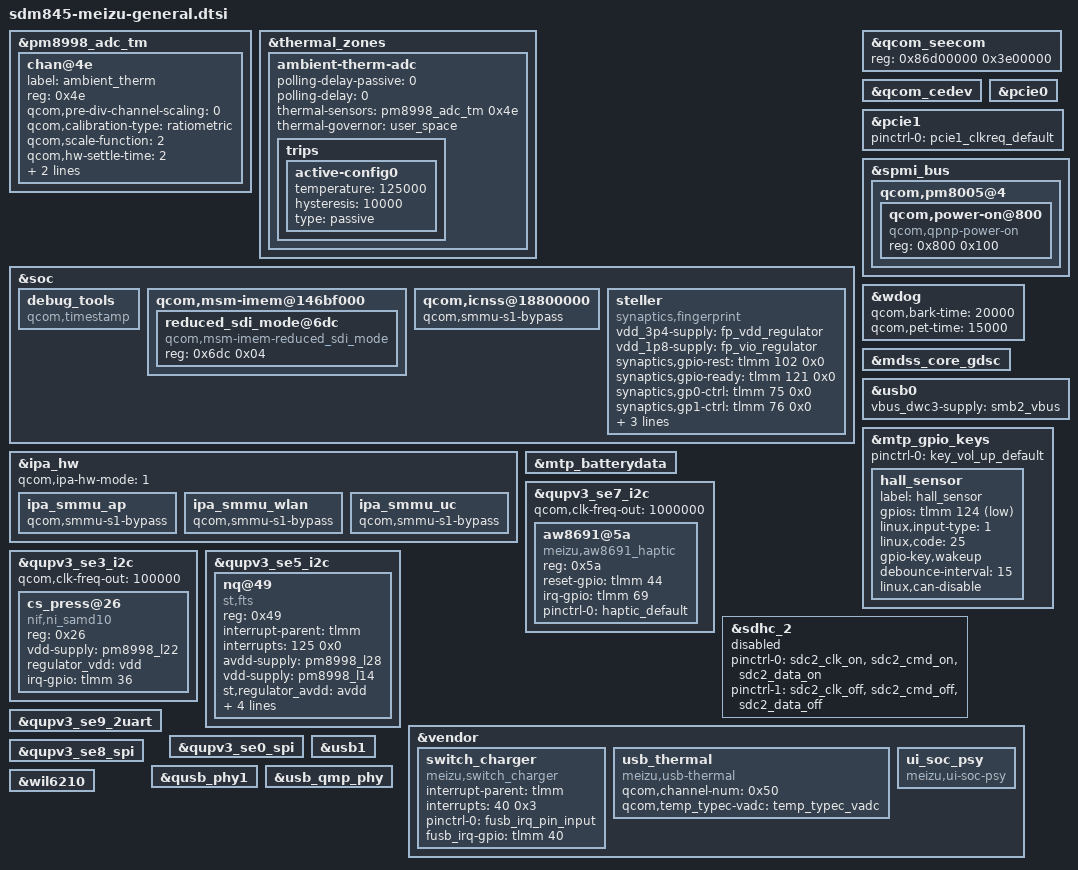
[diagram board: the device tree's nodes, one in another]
/* Copyright (c) 2022, MeizuCustoms enthusiasts
 *
 * This program is free software; you can redistribute it and/or modify
 * it under the terms of the GNU General Public License version 2 and
 * only version 2 as published by the Free Software Foundation.
 *
 * This program is distributed in the hope that it will be useful,
 * but WITHOUT ANY WARRANTY; without even the implied warranty of
 * MERCHANTABILITY or FITNESS FOR A PARTICULAR PURPOSE.  See the
 * GNU General Public License for more details.
 */

&pm8998_adc_tm {
    chan@4e {
        label = "ambient_therm";
        reg = <0x4e>;
        qcom,pre-div-channel-scaling = <0>;
        qcom,calibration-type = "ratiometric";
        qcom,scale-function = <2>;
        qcom,hw-settle-time = <2>;
        qcom,btm-channel-number = <136>;
        qcom,thermal-node;
    };
};

&thermal_zones {
    ambient-therm-adc {
        polling-delay-passive = <0>;
        polling-delay = <0>;
        thermal-sensors = <&pm8998_adc_tm 0x4e>;
        thermal-governor = "user_space";

        trips {

            active-config0 {
                temperature = <125000>;
                hysteresis = <10000>;
                type = "passive";
            };
        };
    };
};

&soc {
    debug_tools {
        status = "ok";
        compatible = "qcom,timestamp";
    };

    qcom,msm-imem@146bf000 {
        reduced_sdi_mode@6dc {
            compatible = "qcom,msm-imem-reduced_sdi_mode";
            reg = <0x6dc 0x04>;
        };
    };

    qcom,icnss@18800000 {
        qcom,smmu-s1-bypass;
    };
};

&ipa_hw {
    qcom,ipa-hw-mode = <1>;
    /delete-property/ qcom,smmu-fast-map;

    ipa_smmu_ap: ipa_smmu_ap {
        qcom,smmu-s1-bypass;
    };

    ipa_smmu_wlan: ipa_smmu_wlan {
        qcom,smmu-s1-bypass;
    };

    ipa_smmu_uc: ipa_smmu_uc {
        qcom,smmu-s1-bypass;
    };
};

&qcom_seecom {
    reg = <0x86d00000 0x3e00000>;
};

&qcom_cedev {
    /delete-node/ qcom_cedev_ns_cb;
    /delete-node/ qcom_cedev_s_cb;
};

&pcie0 {
    /delete-property/ qcom,phy-status-offset;
};

&pcie1 {
    pinctrl-0 = <&pcie1_clkreq_default>;
    /delete-property/ perst-gpio;
    /delete-property/ qcom,phy-status-offset;
};

&spmi_bus {
	qcom,pm8005@4 {
        qcom,power-on@800 {
            compatible = "qcom,qpnp-power-on";
            reg = <0x800 0x100>;
        };
    };
};

&wdog {
    qcom,bark-time = <20000>;
    qcom,pet-time = <15000>;
};

&mdss_core_gdsc {
    /delete-property/ qcom,en-few-wait-val;
    /delete-property/ qcom,en-rest-wait-val;
};

&usb0 {
    vbus_dwc3-supply = <&smb2_vbus>;
};

&mtp_gpio_keys {
    pinctrl-0 = <&key_vol_up_default>;

    hall_sensor {
        label = "hall_sensor";
        gpios = <&tlmm 124 0x1>;
        linux,input-type = <1>;
        linux,code = <25>;
        gpio-key,wakeup;
        debounce-interval = <15>;
        linux,can-disable;
    };

    /delete-node/ cam_snapshot;
    /delete-node/ cam_focus;
};

&mtp_batterydata {
    #include "battery-3511331-meizu-m1882gy-3010mah-averaged-masterslave-jun4th2018.dtsi"
    #include "battery-3511331-meizu-m1882atl-3010mah-averaged-masterslave-jun4th2018.dtsi"
};

&qupv3_se7_i2c {
    status = "ok";
    qcom,clk-freq-out = <1000000>;

    aw8691@5a {
        compatible = "meizu,aw8691_haptic";
        reg = <0x5a>;

        reset-gpio = <&tlmm 44 0x0>;
        irq-gpio = <&tlmm 69 0x0>;

        pinctrl-names = "default";
        pinctrl-0 = <&haptic_default>;
    };
};

&qupv3_se3_i2c {
    status = "ok";
    qcom,clk-freq-out = <100000>;

    cs_press@26 {
        compatible = "nif,ni_samd10";
        reg = <0x26>;
        vdd-supply = <&pm8998_l22>;
        regulator_vdd = "vdd";
        irq-gpio = <&tlmm 36 0x0>;
        status = "okay";
    };
};

&qupv3_se5_i2c {
    status = "ok";

    nq@49 {
        compatible = "st,fts";
        reg = <0x49>;
        interrupt-parent = <&tlmm>;
        interrupts = <125 0x0>;
        avdd-supply = <&pm8998_l28>;
        vdd-supply = <&pm8998_l14>;
        st,regulator_avdd = "avdd";
        st,regulator_dvdd = "vdd";
        st,irq-gpio = <&tlmm 125 0x0>;
        st,reset-gpio = <&tlmm 126 0x0>;
        pinctrl-names = "tp_int";
        pinctrl-0 = <&tp_pins_tp_eint_as_int>;
    };
};

&qupv3_se7_i2c {
    aw8691@5a {
        compatible = "meizu,aw8691_haptic";
        reg = <0x5a>;
        reset-gpio = <&tlmm 44 0x0>;
        pinctrl-names = "default";
        pinctrl-0 = <&haptic_default>;
        irq-gpio = <&tlmm 69 0x0>;
    };
};

&soc {
    steller: steller {
        status = "okay";
        compatible = "synaptics,fingerprint";
        vdd_3p4-supply = <&fp_vdd_regulator>;
        vdd_1p8-supply = <&fp_vio_regulator>;
        synaptics,gpio-rest = <&tlmm 102 0x0>;
        synaptics,gpio-ready = <&tlmm 121 0x0>;
        synaptics,gp0-ctrl = <&tlmm 75 0x0>;
        synaptics,gp1-ctrl = <&tlmm 76 0x0>;
        synaptics,ts-in = <&tlmm 103 0x0>;
        pinctrl-names = "fp_reset_init", "fp_hbm_init";
        pinctrl-0 = <&fp_reset_init>;
        pinctrl-1 = <&fp_hbm_init>;
    };
};

&sdhc_2 {
    pinctrl-0 = <&sdc2_clk_on  &sdc2_cmd_on &sdc2_data_on>;
    pinctrl-1 = <&sdc2_clk_off &sdc2_cmd_off &sdc2_data_off>;

    /delete-property/ cd-gpios;
    /delete-property/ qcom,vdd-voltage-level;
    status = "disabled";
};

&vendor {
    switch_charger {
        compatible = "meizu,switch_charger";
        interrupt-parent = <&tlmm>;
        interrupts = <40 0x3>;
        interrupt-names = "fusb_irq";
        pinctrl-0 = <&fusb_irq_pin_input>;
        pinctrl-names = "default";
        fusb_irq-gpio = <&tlmm 40 0x0>;
    };

    usb_thermal {
        compatible = "meizu,usb-thermal";
        qcom,channel-num = <0x50>;
        qcom,temp_typec-vadc = <&temp_typec_vadc>;
    };

    ui_soc_psy {
        compatible = "meizu,ui-soc-psy";
    };
};

&qupv3_se9_2uart {
    status = "ok";
};

&qupv3_se0_spi {
    status = "ok";
};

&qupv3_se8_spi {
    status = "ok";
};

&usb1 {
    status = "ok";
};

&qusb_phy1 {
    status = "ok";
};

&usb_qmp_phy {
    status = "ok";
};

&wil6210 {
    status = "ok";
};
